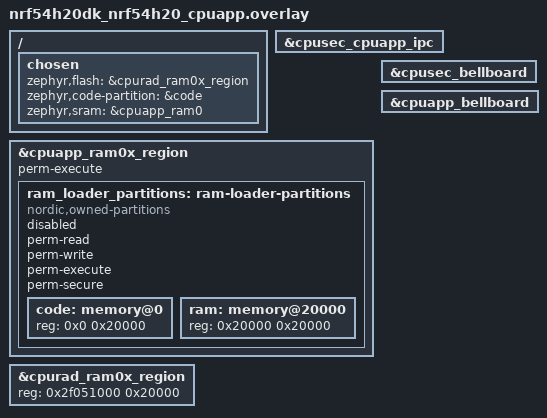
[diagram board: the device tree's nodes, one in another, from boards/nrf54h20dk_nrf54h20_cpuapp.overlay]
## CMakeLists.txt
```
# Copyright (c) 2024 Nordic Semiconductor ASA
# SPDX-License-Identifier: LicenseRef-Nordic-5-Clause

cmake_minimum_required(VERSION 3.20.0)
find_package(Zephyr REQUIRED HINTS $ENV{ZEPHYR_BASE})

project(ram_loader)
target_sources(app PRIVATE src/main.c)
```

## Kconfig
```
# Copyright (c) 2024 Nordic Semiconductor ASA
# SPDX-License-Identifier: LicenseRef-Nordic-5-Clause

menu "RAM Loader"

config NRF_KEY_LOADER
	default y

config NRF_KEY_LOADER_BASE_PATH
	default "${ZEPHYR_NRF_MODULE_DIR}/applications/ram_loader/keys"

config SSF_ECHO_SERVICE_ENABLED
	default y

endmenu

menu "Zephyr Kernel"
source "Kconfig.zephyr"
endmenu
```

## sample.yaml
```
sample:
  name: Domain Asset loader
  description: |
    Used for loading assets for a domain

common:
  build_only: true

tests:
  mram:
    platform_allow: nrf54h20dk/nrf54h20/cpuapp
    integration_platforms:
      - nrf54h20dk/nrf54h20/cpuapp
    extra_args:
      - EXTRA_DTC_OVERLAY_FILE=run_from_mram.overlay
      - EXTRA_CONF_FILE=run_from_mram.conf
      - SB_CONFIG_SUIT_ENVELOPE=y
      - SNIPPET=crypto_service
  ram:
    platform_allow: nrf54h20dk/nrf54h20/cpuapp
    integration_platforms:
      - nrf54h20dk/nrf54h20/cpuapp
    extra_args: EXTRA_CONF_FILE=run_from_ram.conf
    extra_args:
      - EXTRA_CONF_FILE=run_from_ram.conf
      - SB_CONFIG_SUIT_ENVELOPE=n
      - SNIPPET=crypto_service
```

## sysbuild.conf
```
SB_CONFIG_SUIT_ENVELOPE=n
```

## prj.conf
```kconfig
# Build
CONFIG_SIZE_OPTIMIZATIONS=y

# The Zephyr CMSIS emulation assumes that ticks are ms, currently
CONFIG_SYS_CLOCK_TICKS_PER_SEC=1000

CONFIG_MAIN_STACK_SIZE=2048
CONFIG_HEAP_MEM_POOL_SIZE=2048

# Enable nordic security backend and PSA APIs
CONFIG_NRF_SECURITY=y
CONFIG_MBEDTLS_PSA_CRYPTO_C=y

CONFIG_CONSOLE=y
CONFIG_LOG=y

CONFIG_MBEDTLS_ENABLE_HEAP=y
CONFIG_MBEDTLS_HEAP_SIZE=8192

# Enable this to build stand-alone
CONFIG_SUIT_LOCAL_ENVELOPE_GENERATE=n
CONFIG_SUIT_ENVELOPE_TARGET=""
CONFIG_NRF_REGTOOL_GENERATE_UICR=n
CONFIG_SUIT_MPI_GENERATE=n
CONFIG_SUIT_ENVELOPE_OUTPUT_MPI_MERGE=n

# Bugfixes
CONFIG_NRFS_MRAM_SERVICE_ENABLED=n
CONFIG_DCACHE=n
```

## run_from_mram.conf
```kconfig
# Use 'code-partition' chosen.
CONFIG_USE_DT_CODE_PARTITION=y
CONFIG_SUIT_LOCAL_ENVELOPE_GENERATE=y
CONFIG_NRF_REGTOOL_GENERATE_UICR=y
CONFIG_SUIT_MPI_GENERATE=y
CONFIG_SUIT_ENVELOPE_OUTPUT_MPI_MERGE=y
CONFIG_SUIT_ENVELOPE_TARGET="application"
```

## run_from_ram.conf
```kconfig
# Disable SUIT since this application is booted by the debugger directly

CONFIG_SUIT_LOCAL_ENVELOPE_GENERATE=n
CONFIG_SUIT_ENVELOPE_TARGET=""
CONFIG_SUIT_MPI_GENERATE=n
CONFIG_SUIT_ENVELOPE_OUTPUT_MPI_MERGE=n

# The UICR from "parent" image is used, no need for this.
# CONFIG_NRF_REGTOOL_GENERATE_UICR=n

# Don't use 'code-partition' chosen.
CONFIG_USE_DT_CODE_PARTITION=n
```

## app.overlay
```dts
/ {
	chosen {
		zephyr,flash = &cpuapp_data;
		zephyr,code-partition = &cpuapp_data;
		zephyr,sram = &cpuapp_ram0;
	};
};
```

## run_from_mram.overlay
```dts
/*
 * Copyright (c) 2024 Nordic Semiconductor ASA
 *
 * SPDX-License-Identifier: LicenseRef-Nordic-5-Clause
 */


/ {
	chosen {
		zephyr,flash = &mram1x;
		zephyr,code-partition = &cpuapp_slot0_partition;
		zephyr,sram = &cpuapp_data;
	};
};
```

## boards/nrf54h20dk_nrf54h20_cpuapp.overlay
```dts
/*
 * Copyright (c) 2024 Nordic Semiconductor ASA
 *
 * SPDX-License-Identifier: LicenseRef-Nordic-5-Clause
 */


&cpusec_cpuapp_ipc {
	status = "okay";
};

&cpuapp_ram0x_region {
	status = "okay";
};

&cpusec_bellboard {
	status = "okay";
};

&cpuapp_bellboard {
	status = "okay";
};

&cpurad_ram0x_region {
	reg = < 0x2f051000 0x20000 >;
	ranges = < 0x0 0x2f051000 0x20000 >;
};

&cpuapp_ram0x_region {
	perm-execute;

	ram_loader_partitions: ram-loader-partitions {
		compatible = "nordic,owned-partitions", "fixed-partitions";
		status = "disabled";
		perm-read;
		perm-write;
		perm-execute;
		perm-secure;
		#address-cells = <1>;
		#size-cells = <1>;

		code: memory@0 {
			reg = < 0x0 0x20000>;
		};
		ram: memory@20000{
			reg = < 0x20000 0x20000>;
		};
	};
};

/ {
	chosen {
		zephyr,flash = &cpurad_ram0x_region;
		zephyr,code-partition = &code;
		zephyr,sram = &cpuapp_ram0;
	};
};
```

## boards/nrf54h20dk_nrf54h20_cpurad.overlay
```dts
/*
 * Copyright (c) 2024 Nordic Semiconductor ASA
 *
 * SPDX-License-Identifier: LicenseRef-Nordic-5-Clause
 */

&cpusec_cpurad_ipc {
	status = "okay";
};

&cpurad_ram0x_region {
	status = "okay";
};

&cpusec_bellboard {
	status = "okay";
};

&cpurad_bellboard {
	status = "okay";
};

&cpuapp_ram0x_region {
	ram_loader_partitions: ram-loader-partitions {
		compatible = "nordic,owned-partitions", "fixed-partitions";
		status = "disabled";
		perm-read;
		perm-write;
		perm-execute;
		perm-secure;
		#address-cells = <1>;
		#size-cells = <1>;

		code: memory@0 {
			reg = < 0x0 0x20000>;
		};
		ram: memory@20000{
			reg = < 0x20000 0x20000>;
		};
	};
};

/ {
	chosen {
		zephyr,flash = &cpuapp_ram0x_region;
		zephyr,code-partition = &code;
		zephyr,sram = &ram;
	};
};
```

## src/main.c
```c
/*
 * Copyright (c) 2024 Nordic Semiconductor ASA
 * SPDX-License-Identifier: Apache-2.0
 */

#include <zephyr/sys/printk.h>
#include <zephyr/linker/linker-defs.h>

#include <psa/crypto.h>

#include <sdfw/sdfw_services/echo_service.h>

static void echo_request(void)
{
	int err;
	char req_str[] = "wat";
	char rsp_str[sizeof(req_str) + 1];

	printk("Calling ssf_echo, str: \"%s\"", req_str);

	err = ssf_echo(req_str, rsp_str, sizeof(rsp_str));
	if (err != 0) {
		printk("ssf_echo failed");
	} else {
		printk("ssf_echo response: %s", rsp_str);
	}
}

int main(void)
{
	printk("RAM loader running from %p\n", __rom_region_start);

	echo_request();

	return 0;
}
```
